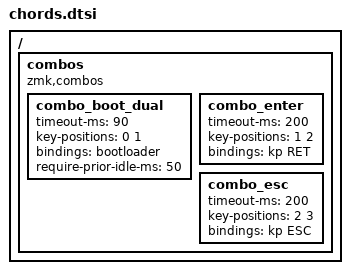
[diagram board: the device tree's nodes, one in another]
/ {
    combos {
        compatible = "zmk,combos";

        combo_boot_dual {
            timeout-ms = <90>;
            key-positions = <0 1>;
            bindings = <&bootloader>;
            require-prior-idle-ms = <50>;
        };

        combo_enter {
            timeout-ms = <200>;
            key-positions = <1 2>;
            bindings = <&kp RET>;
        };

        combo_esc {
            timeout-ms = <200>;
            key-positions = <2 3>;
            bindings = <&kp ESC>;
        };
    };
};

